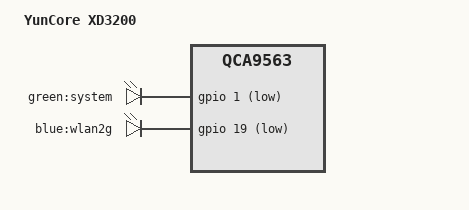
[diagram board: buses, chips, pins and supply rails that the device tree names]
// SPDX-License-Identifier: GPL-2.0-or-later OR MIT

#include "qca9563_yuncore_xd4200.dtsi"

/ {
	compatible = "yuncore,xd3200", "qca,qca9563";
	model = "YunCore XD3200";

	aliases {
		label-mac-device = &eth0;
		led-boot = &led_system;
		led-failsafe = &led_system;
		led-running = &led_system;
		led-upgrade = &led_system;
	};

	leds {
		compatible = "gpio-leds";

		led_system: system {
			label = "green:system";
			gpios = <&gpio 1 GPIO_ACTIVE_LOW>;
			default-state = "keep";
		};

		wlan2g {
			label = "blue:wlan2g";
			gpios = <&gpio 19 GPIO_ACTIVE_LOW>;
			linux,default-trigger = "phy1tpt";
		};
	};
};

&pcie {
	wifi@0,0 {
		nvmem-cells = <&cal_art_5000>;
		nvmem-cell-names = "calibration";
	};
};
